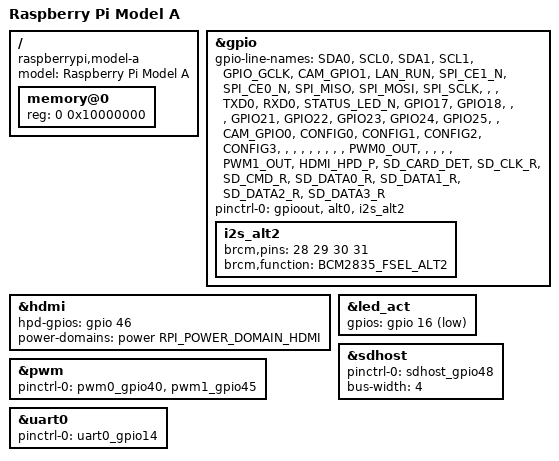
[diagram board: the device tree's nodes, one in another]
/dts-v1/;
#include "bcm2835.dtsi"
#include "bcm2835-rpi.dtsi"
#include "bcm2835-rpi-common.dtsi"
#include "bcm283x-rpi-led-deprecated.dtsi"
#include "bcm283x-rpi-usb-host.dtsi"
/ {
	compatible = "raspberrypi,model-a", "brcm,bcm2835";
	model = "Raspberry Pi Model A";
	memory@0 {
		device_type = "memory";
		reg = <0 0x10000000>;
	};
};
&gpio {
	gpio-line-names = "SDA0",
			  "SCL0",
			  "SDA1",
			  "SCL1",
			  "GPIO_GCLK",
			  "CAM_GPIO1",
			  "LAN_RUN",
			  "SPI_CE1_N",
			  "SPI_CE0_N",
			  "SPI_MISO",
			  "SPI_MOSI",
			  "SPI_SCLK",
			  "",  
			  "",  
			  "TXD0",
			  "RXD0",
			  "STATUS_LED_N",
			  "GPIO17",
			  "GPIO18",
			  "",  
			  "",  
			  "GPIO21",
			  "GPIO22",
			  "GPIO23",
			  "GPIO24",
			  "GPIO25",
			  "",  
			  "CAM_GPIO0",
			  "CONFIG0",
			  "CONFIG1",
			  "CONFIG2",
			  "CONFIG3",
			  "",  
			  "",  
			  "",  
			  "",  
			  "",  
			  "",  
			  "",  
			  "",  
			  "PWM0_OUT",
			  "",  
			  "",  
			  "",  
			  "",  
			  "PWM1_OUT",
			  "HDMI_HPD_P",
			  "SD_CARD_DET",
			  "SD_CLK_R",
			  "SD_CMD_R",
			  "SD_DATA0_R",
			  "SD_DATA1_R",
			  "SD_DATA2_R",
			  "SD_DATA3_R";
	pinctrl-names = "default";
	pinctrl-0 = <&gpioout &alt0 &i2s_alt2>;
	i2s_alt2: i2s_alt2 {
		brcm,pins = <28 29 30 31>;
		brcm,function = <BCM2835_FSEL_ALT2>;
	};
};
&hdmi {
	hpd-gpios = <&gpio 46 GPIO_ACTIVE_HIGH>;
	power-domains = <&power RPI_POWER_DOMAIN_HDMI>;
	status = "okay";
};
&led_act {
	gpios = <&gpio 16 GPIO_ACTIVE_LOW>;
};
&pwm {
	pinctrl-names = "default";
	pinctrl-0 = <&pwm0_gpio40 &pwm1_gpio45>;
	status = "okay";
};
&sdhost {
	pinctrl-names = "default";
	pinctrl-0 = <&sdhost_gpio48>;
	bus-width = <4>;
	status = "okay";
};
&uart0 {
	pinctrl-names = "default";
	pinctrl-0 = <&uart0_gpio14>;
	status = "okay";
};
